# STM32U599xx register map
File version: 1.0
Registers are 32-bit, read-write, reset 0x0 unless marked. A register's access mark holds for its fields unless they carry their own. Offsets are from the block's base; [hi:lo] are bit positions; 'fields as' and 'values as' point back to an identical list.

## OPAMP1 — Operational Amplifier (OPAMP)
Base 0x46005000; alternate view of OPAMP12_COMMON
Same registers: OPAMP 0x46005000, OPAMP2 0x46005010, OPAMP1_S 0x56005000 (alternate view of OPAMP12_COMMON_S), OPAMP_S 0x56005000 (alternate view of OPAMP12_COMMON_S), OPAMP2_S 0x56005010
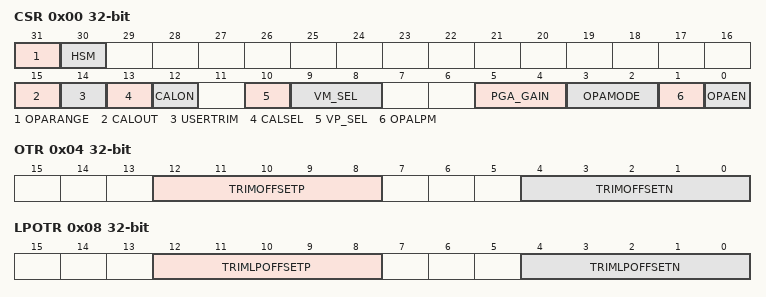
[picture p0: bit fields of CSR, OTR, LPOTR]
0x00 CSR — OPAMP control/status register
  [31] OPARANGE — Operational amplifier range setting
    0=LOW (Power supply range low); 1=HIGH (Power supply range high - recommended for performance purpose)
  [30] HSM — Operational amplifier high speed mode
  [15] CALOUT — Operational amplifier calibration output
  [14] USERTRIM — User trimming enable
    0=FACTORY (OPAMP trimming factors set to factory values); 1=USER (OPAMP trimming factors set to user values)
  [13] CALSEL — Calibration selection
  [12] CALON — Calibration mode enable
    0=FUNCTIONAL (OPAMP functional mode); 1=CALIBRATION (OPAMP calibration mode)
  [10] VP_SEL — Non inverted input selection
    0=IO0 (OPAMP non inverting input connected to GPIO pin (pin PA0 for OPAMP1, pin PA6 for OPAMP2)); 1=DAC (OPAMP non inverting input connected to DAC1 channel output(channel1 for OPAMP1, channel2 for OPAMP2))
  [9:8] VM_SEL — Inverting input selection
    0=IO0 (OPAMP inverting input connected to GPIO pin (valid also in PGA mode for filtering). Note: OPAMP inverting input is used with OPAMP in mode standalone or PGA with external capacitors for filtering circuit. Otherwise (OPAMP in mode follower), OPAMP inverting input is not used (not connected to GPIO pin).); 1=IO1 (OPAMP inverting input (low leakage input) connected to GPIO pin (available only on package BGA132). Note: OPAMP inverting input is used with OPAMP in mode standalone or PGA with external capacitors for filtering circuit. Otherwise (OPAMP in mode follower), OPAMP inverting input is not used (not connected to GPIO pin).); 2=CONNECT_NO (OPAMP inverting input not externally connected (intended for OPAMP in mode follower or PGA without external capacitors for filtering))
  [5:4] PGA_GAIN — Operational amplifier Programmable amplifier gain value
    0=GAIN_2 (OPAMP PGA gain 2); 1=GAIN_4 (OPAMP PGA gain 4); 2=GAIN_8 (OPAMP PGA gain 8); 3=GAIN_16 (OPAMP PGA gain 16)
  [3:2] OPAMODE — Operational amplifier PGA mode
    0=STANDALONE (OPAMP functional mode, OPAMP operation in standalone); 3=FOLLOWER (OPAMP functional mode, OPAMP operation in follower); 2=PGA (OPAMP functional mode, OPAMP operation in PGA)
  [1] OPALPM — Operational amplifier Low Power Mode
  [0] OPAEN — OPAMP enable
0x04 OTR — OPAMP
  [12:8] TRIMOFFSETP — Trim for PMOS differential pairs
  [4:0] TRIMOFFSETN — Trim for NMOS differential pairs
0x08 LPOTR — OPAMP
  [12:8] TRIMLPOFFSETP — Trim for PMOS differential pairs
  [4:0] TRIMLPOFFSETN — Trim for NMOS differential pairs

## COMP12 — Comparator
Base 0x46005400
Same registers: COMP12_S 0x56005400
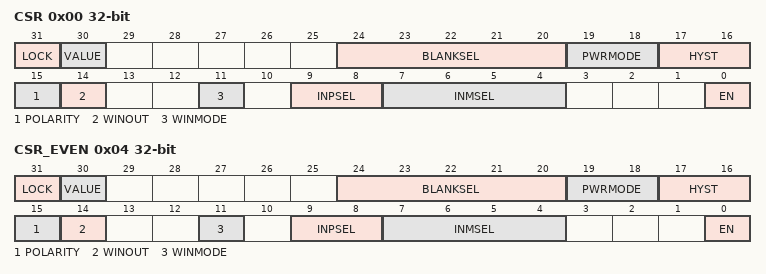
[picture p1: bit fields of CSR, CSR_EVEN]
0x00 CSR — Comparator control and status register
  [31] LOCK — Comparator lock
  [30] VALUE — Comparator output level
  [24:20] BLANKSEL — Comparator blanking source
    0=NONE (Comparator output without blanking); 1=TIM1_OC5 (Comparator output blanking source TIM1 OC5 for COMP1 Instance); 2=TIM2_OC3 (Comparator output blanking source TIM2 OC3 for COMP1 Instance); 4=TIM3_OC3 (Comparator output blanking source TIM3 OC3 for COMP1 Instance)
  [19:18] PWRMODE — Comparator power mode
    0=HIGHSPEED (COMP power mode to high speed); 1=MEDIUMSPEED (COMP power mode to medium speed); 3=ULTRALOWPOWER (COMP power mode to ultra-low power)
  [17:16] HYST — Comparator input hysteresis
    0=NONE (No hysteresis); 1=LOW (Hysteresis level low); 2=MEDIUM (Hysteresis level medium); 3=HIGH (Hysteresis level high)
  [15] POLARITY — Comparator output polarity
    0=NONINVERTED (COMP output polarity is not inverted: comparator output is high when the plus (non-inverting) input is at a higher voltage than the minus (inverting) input); 1=INVERTED (COMP output polarity is inverted: comparator output is low when the plus (non-inverting) input is at a lower voltage than the minus (inverting) input)
  [14] WINOUT — Pair of comparators window output level. Bit intended to be used with COMP common instance (COMP_Common_TypeDef)
  [11] WINMODE — Pair of comparators window mode. Bit intended to be used with COMP common instance (COMP_Common_TypeDef)
  [9:8] INPSEL — Comparator input plus selection
    0=IO1 (Comparator input plus connected to IO1 (pin PC5 for COMP1, pin PB4 for COMP2)); 1=IO2 (Comparator input plus connected to IO2 (pin PB2 for COMP1, pin PB6 for COMP2)); 2=IO3 (Comparator input plus connected to IO3 (pin PA2 for COMP1))
  [7:4] INMSEL — Comparator input minus selection
    0=MINUS_1_4VREFINT (Comparator input minus connected to 1/4 VrefInt); 1=MINUS_1_2VREFINT (Comparator input minus connected to 1/2 VrefInt); 2=MINUS_3_4VREFINT (Comparator input minus connected to 3/4 VrefInt); 3=VREFINT (Comparator input minus connected to VrefInt); 4=DAC1_CH1 (Comparator input minus connected to DAC1 channel 1 (DAC_OUT1)); 5=DAC1_CH2 (Comparator input minus connected to DAC1 channel 2 (DAC_OUT2)); 6=IO1 (Comparator input minus connected to IO1 (pin PB1 for COMP1, pin PB3 for COMP2)); 7=IO2 (Comparator input minus connected to IO2 (pin PC4 for COMP1, pin PB7 for COMP2))
  [0] EN — Comparator enable
0x04 CSR_EVEN — COMP control and status register located in register of comparator instance even, used for bits common to several COMP instances
  fields as CSR
